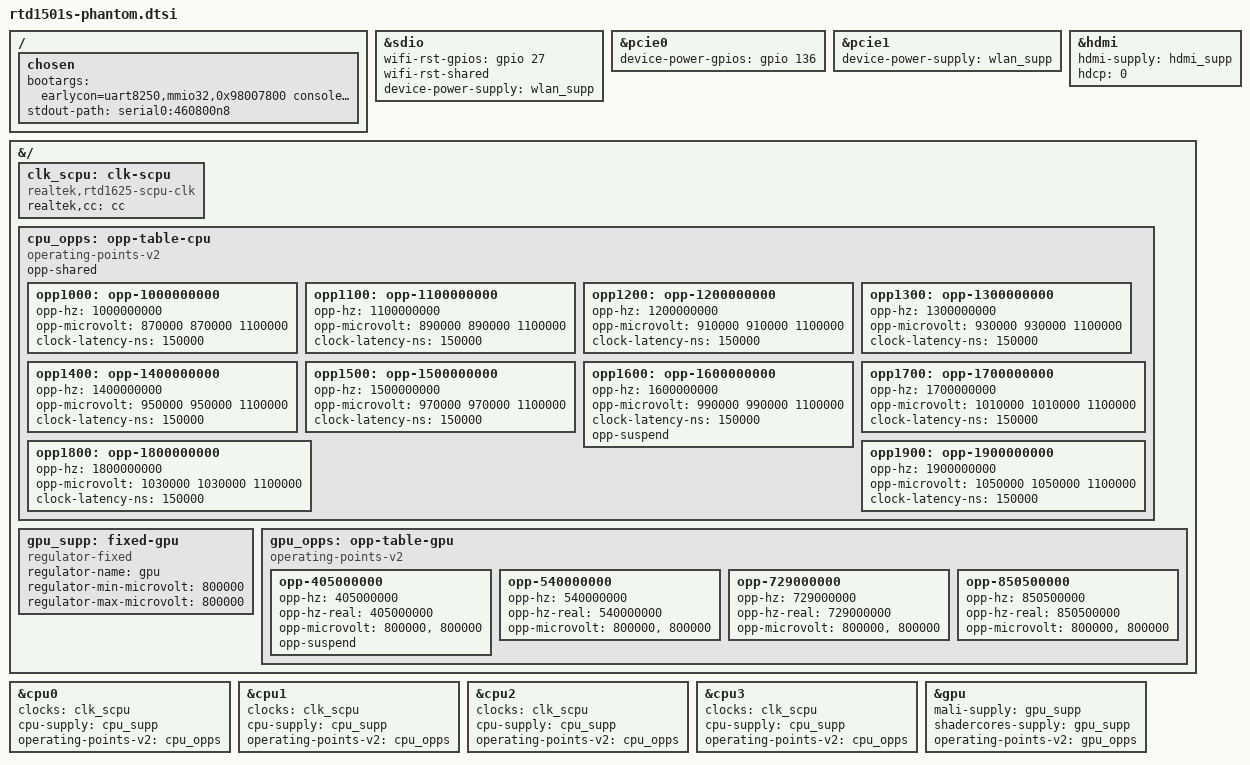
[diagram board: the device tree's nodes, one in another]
// SPDX-License-Identifier: (GPL-2.0-or-later OR BSD-2-Clause)
/*
 * Realtek RTD1501S Phantom EVB
 *
 * Copyright (c) 2024 Realtek Semiconductor Corp.
 */

/dts-v1/;

#include <dt-bindings/thermal/thermal.h>
#include "rtd1501.dtsi"
#include "rtd1501s-phantom.rds.dtsi"

/ {
	chosen {
		bootargs = "earlycon=uart8250,mmio32,0x98007800 console=ttyS0,460800 8250.nr_uarts=2 8250.share_irqs=1 init=/init loglevel=8 max_loop=64 loop.max_part=7 firmware_class.path=/vendor/firmware/";
		stdout-path = "serial0:460800n8";
	};
};

&sdio {
	wifi-rst-gpios = <&gpio 27 GPIO_ACTIVE_HIGH>;
	wifi-rst-shared;
	device-power-supply = <&wlan_supp>;
};

&pcie0 {
	device-power-gpios = <&gpio 136 GPIO_ACTIVE_HIGH>;
};

&pcie1 {
	device-power-supply = <&wlan_supp>;
};

&hdmi {
	hdmi-supply = <&hdmi_supp>;
	hdcp = <0>;
};

&{/} {
	clk_scpu: clk-scpu {
		compatible = "realtek,rtd1625-scpu-clk";
		realtek,cc = <&cc>;
		#clock-cells = <0>;
	};

	cpu_opps: opp-table-cpu {
		compatible = "operating-points-v2";
		opp-shared;

		opp1000: opp-1000000000 {
			opp-hz = /bits/ 64 <1000000000>;
			opp-microvolt = <870000 870000 1100000>;
			clock-latency-ns = <150000>;
			status = "okay";
		};

		opp1100: opp-1100000000 {
			opp-hz = /bits/ 64 <1100000000>;
			opp-microvolt = <890000 890000 1100000>;
			clock-latency-ns = <150000>;
			status = "okay";
		};

		opp1200: opp-1200000000 {
			opp-hz = /bits/ 64 <1200000000>;
			opp-microvolt = <910000 910000 1100000>;
			clock-latency-ns = <150000>;
			status = "okay";
		};

		opp1300: opp-1300000000 {
			opp-hz = /bits/ 64 <1300000000>;
			opp-microvolt = <930000 930000 1100000>;
			clock-latency-ns = <150000>;
			status = "okay";
		};

		opp1400: opp-1400000000 {
			opp-hz = /bits/ 64 <1400000000>;
			opp-microvolt = <950000 950000 1100000>;
			clock-latency-ns = <150000>;
			status = "okay";
		};

		opp1500: opp-1500000000 {
			opp-hz = /bits/ 64 <1500000000>;
			opp-microvolt = <970000 970000 1100000>;
			clock-latency-ns = <150000>;
			status = "okay";
		};

		opp1600: opp-1600000000 {
			opp-hz = /bits/ 64 <1600000000>;
			opp-microvolt = <990000 990000 1100000>;
			clock-latency-ns = <150000>;
			opp-suspend;
			status = "okay";
		};

		opp1700: opp-1700000000 {
			opp-hz = /bits/ 64 <1700000000>;
			opp-microvolt = <1010000 1010000 1100000>;
			clock-latency-ns = <150000>;
			status = "okay";
		};

		opp1800: opp-1800000000 {
			opp-hz = /bits/ 64 <1800000000>;
			opp-microvolt = <1030000 1030000 1100000>;
			clock-latency-ns = <150000>;
			status = "okay";
		};

		opp1900: opp-1900000000 {
			opp-hz = /bits/ 64 <1900000000>;
			opp-microvolt = <1050000 1050000 1100000>;
			clock-latency-ns = <150000>;
			status = "okay";
		};
	};
};

&cpu0 {
	clocks = <&clk_scpu>;
	cpu-supply = <&cpu_supp>;
	operating-points-v2 = <&cpu_opps>;
	#cooling-cells = <2>;
};

&cpu1 {
	clocks = <&clk_scpu>;
	cpu-supply = <&cpu_supp>;
	operating-points-v2 = <&cpu_opps>;
	#cooling-cells = <2>;
};

&cpu2 {
	clocks = <&clk_scpu>;
	cpu-supply = <&cpu_supp>;
	operating-points-v2 = <&cpu_opps>;
	#cooling-cells = <2>;
};

&cpu3 {
	clocks = <&clk_scpu>;
	cpu-supply = <&cpu_supp>;
	operating-points-v2 = <&cpu_opps>;
	#cooling-cells = <2>;
};

&gpu {
	mali-supply = <&gpu_supp>;
	shadercores-supply = <&gpu_supp>;
	operating-points-v2 = <&gpu_opps>;
};

&{/} {
	gpu_supp: fixed-gpu {
		compatible = "regulator-fixed";
		regulator-name = "gpu";
		regulator-min-microvolt = <800000>;
		regulator-max-microvolt = <800000>;
	};

	gpu_opps: opp-table-gpu {
		compatible = "operating-points-v2", "operating-points-v2-mali";

		opp-405000000 {
			opp-hz = /bits/ 64 <405000000>;
			opp-hz-real = /bits/ 64 <405000000>;
			opp-microvolt = <800000>, <800000>;
			opp-suspend;
		};

		opp-540000000 {
			opp-hz = /bits/ 64 <540000000>;
			opp-hz-real = /bits/ 64 <540000000>;
			opp-microvolt = <800000>, <800000>;
		};

		opp-729000000 {
			opp-hz = /bits/ 64 <729000000>;
			opp-hz-real = /bits/ 64 <729000000>;
			opp-microvolt = <800000>, <800000>;
		};

		opp-850500000 {
			opp-hz = /bits/ 64 <850500000>;
			opp-hz-real = /bits/ 64 <850500000>;
			opp-microvolt = <800000>, <800000>;
		};
	};
};
